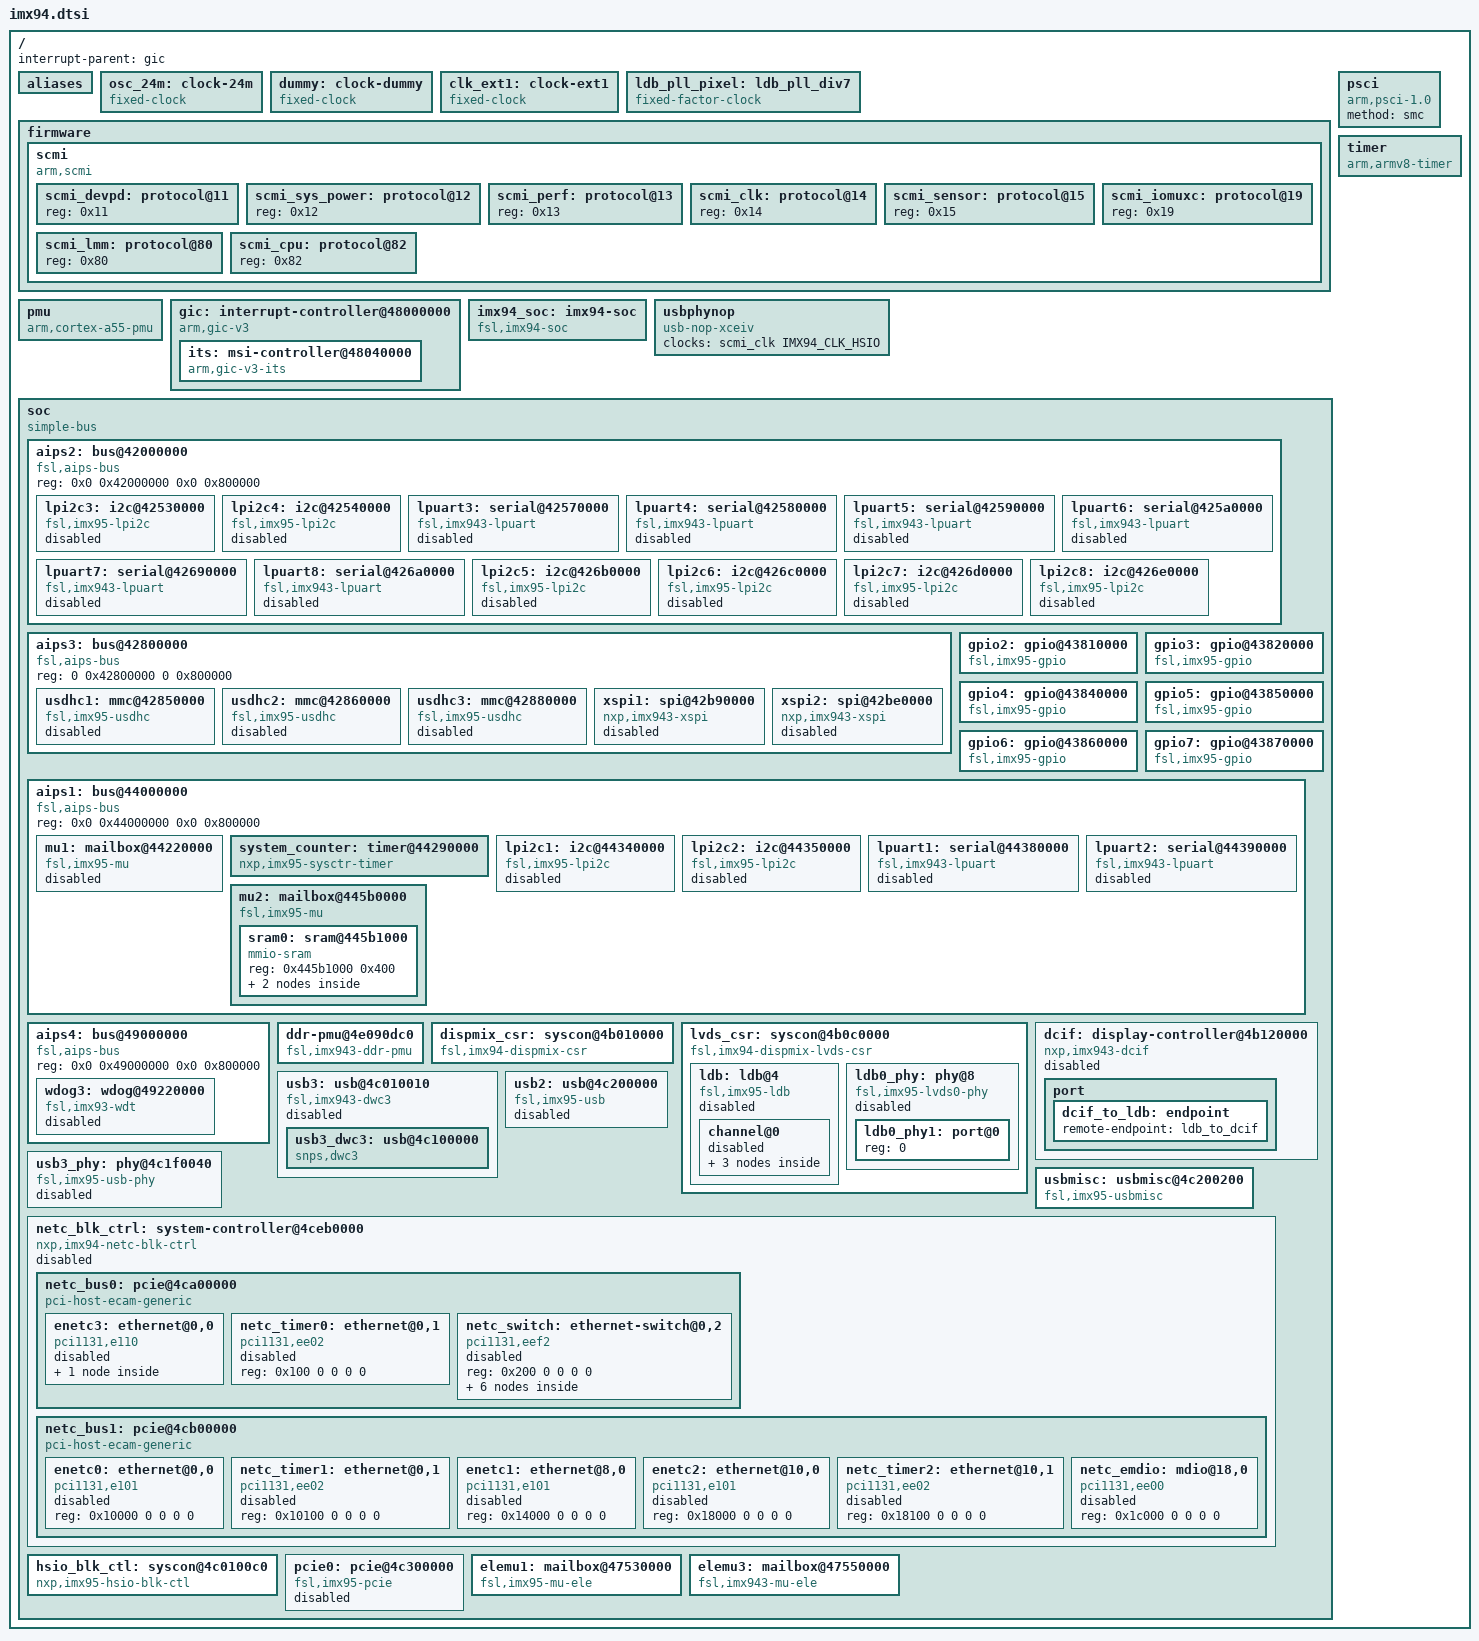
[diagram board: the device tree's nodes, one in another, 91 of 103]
// SPDX-License-Identifier: (GPL-2.0+ OR MIT)
/*
 * Copyright 2024-2025 NXP
 */

#include <dt-bindings/clock/nxp,imx94-clock.h>
#include <dt-bindings/gpio/gpio.h>
#include <dt-bindings/input/input.h>
#include <dt-bindings/interrupt-controller/arm-gic.h>
#include <dt-bindings/thermal/thermal.h>

#include "imx94-clock.h"
#include "imx94-pinfunc.h"
#include "imx94-power.h"

/ {
	#address-cells = <2>;
	#size-cells = <2>;
	interrupt-parent = <&gic>;

	aliases {
		gpio1 = &gpio2;
		gpio2 = &gpio3;
		gpio3 = &gpio4;
		gpio4 = &gpio5;
		gpio5 = &gpio6;
		gpio6 = &gpio7;
		i2c0 = &lpi2c1;
		i2c1 = &lpi2c2;
		i2c2 = &lpi2c3;
		i2c3 = &lpi2c4;
		i2c4 = &lpi2c5;
		i2c5 = &lpi2c6;
		i2c6 = &lpi2c7;
		i2c7 = &lpi2c8;
		mmc0 = &usdhc1;
		mmc1 = &usdhc2;
		mmc2 = &usdhc3;
		serial0 = &lpuart1;
		serial1 = &lpuart2;
		serial2 = &lpuart3;
		serial3 = &lpuart4;
		serial4 = &lpuart5;
		serial5 = &lpuart6;
		serial6 = &lpuart7;
		serial7 = &lpuart8;
	};

	osc_24m: clock-24m {
		compatible = "fixed-clock";
		#clock-cells = <0>;
		clock-frequency = <24000000>;
		clock-output-names = "osc_24m";
	};

	dummy: clock-dummy {
		compatible = "fixed-clock";
		#clock-cells = <0>;
		clock-frequency = <0>;
		clock-output-names = "dummy";
	};

	clk_ext1: clock-ext1 {
		compatible = "fixed-clock";
		#clock-cells = <0>;
		clock-frequency = <133000000>;
		clock-output-names = "clk_ext1";
	};

	ldb_pll_pixel: ldb_pll_div7 {
		#clock-cells = <0>;
		compatible = "fixed-factor-clock";
		clocks = <&scmi_clk IMX94_CLK_LDBPLL>;
		clock-div = <7>;
		clock-mult = <1>;
		clock-output-names = "ldb_pll_div7";
	};

	firmware {
		scmi {
			compatible = "arm,scmi";
			#address-cells = <1>;
			#size-cells = <0>;
			mboxes = <&mu2 5 0>, <&mu2 3 0>, <&mu2 3 1>;
			shmem = <&scmi_buf0>;

			scmi_devpd: protocol@11 {
				reg = <0x11>;
				#power-domain-cells = <1>;
			};

			scmi_sys_power: protocol@12 {
				reg = <0x12>;
			};

			scmi_perf: protocol@13 {
				reg = <0x13>;
				#power-domain-cells = <1>;
			};

			scmi_clk: protocol@14 {
				reg = <0x14>;
				#clock-cells = <1>;
			};

			scmi_sensor: protocol@15 {
				reg = <0x15>;
				#thermal-sensor-cells = <1>;
			};

			scmi_iomuxc: protocol@19 {
				reg = <0x19>;
			};

			scmi_lmm: protocol@80 {
				reg = <0x80>;
			};

			scmi_cpu: protocol@82 {
				reg = <0x82>;
			};
		};
	};

	pmu {
		compatible = "arm,cortex-a55-pmu";
		interrupts = <GIC_PPI 7 (GIC_CPU_MASK_SIMPLE(6) | IRQ_TYPE_LEVEL_HIGH)>;
	};

	psci {
		compatible = "arm,psci-1.0";
		method = "smc";
	};

	timer {
		compatible = "arm,armv8-timer";
		interrupts = <GIC_PPI 13 (GIC_CPU_MASK_SIMPLE(6) | IRQ_TYPE_LEVEL_LOW)>,
			     <GIC_PPI 14 (GIC_CPU_MASK_SIMPLE(6) | IRQ_TYPE_LEVEL_LOW)>,
			     <GIC_PPI 11 (GIC_CPU_MASK_SIMPLE(6) | IRQ_TYPE_LEVEL_LOW)>,
			     <GIC_PPI 10 (GIC_CPU_MASK_SIMPLE(6) | IRQ_TYPE_LEVEL_LOW)>;
		clock-frequency = <24000000>;
		interrupt-parent = <&gic>;
		arm,no-tick-in-suspend;
	};

	gic: interrupt-controller@48000000 {
		compatible = "arm,gic-v3";
		reg = <0 0x48000000 0 0x10000>,
		      <0 0x48060000 0 0xc0000>;
		ranges;
		#interrupt-cells = <3>;
		interrupt-controller;
		interrupts = <GIC_PPI 9 IRQ_TYPE_LEVEL_HIGH>;
		#address-cells = <2>;
		#size-cells = <2>;
		dma-noncoherent;
		interrupt-parent = <&gic>;

		its: msi-controller@48040000 {
			compatible = "arm,gic-v3-its";
			reg = <0 0x48040000 0 0x20000>;
			#msi-cells = <1>;
			dma-noncoherent;
			msi-controller;
		};
	};

	imx94_soc: imx94-soc {
		compatible = "fsl,imx94-soc";
	};

	usbphynop: usbphynop {
		compatible = "usb-nop-xceiv";
		#phy-cells = <0>;
		clocks = <&scmi_clk IMX94_CLK_HSIO>;
		clock-names = "main_clk";
	};

	soc {
		compatible = "simple-bus";
		ranges;
		#address-cells = <2>;
		#size-cells = <2>;

		aips2: bus@42000000 {
			compatible = "fsl,aips-bus", "simple-bus";
			reg = <0x0 0x42000000 0x0 0x800000>;
			ranges = <0x42000000 0x0 0x42000000 0x8000000>;
			#address-cells = <1>;
			#size-cells = <1>;

			lpi2c3: i2c@42530000 {
				compatible = "fsl,imx95-lpi2c", "fsl,imx7ulp-lpi2c";
				reg = <0x42530000 0x10000>;
				interrupts = <GIC_SPI 67 IRQ_TYPE_LEVEL_HIGH>;
				#address-cells = <1>;
				#size-cells = <0>;
				clocks = <&scmi_clk IMX94_CLK_LPI2C3>,
					 <&scmi_clk IMX94_CLK_BUSWAKEUP>;
				clock-names = "per", "ipg";
				status = "disabled";
			};

			lpi2c4: i2c@42540000 {
				compatible = "fsl,imx95-lpi2c", "fsl,imx7ulp-lpi2c";
				reg = <0x42540000 0x10000>;
				interrupts = <GIC_SPI 68 IRQ_TYPE_LEVEL_HIGH>;
				#address-cells = <1>;
				#size-cells = <0>;
				clocks = <&scmi_clk IMX94_CLK_LPI2C4>,
					 <&scmi_clk IMX94_CLK_BUSWAKEUP>;
				clock-names = "per", "ipg";
				status = "disabled";
			};

			lpuart3: serial@42570000 {
				compatible = "fsl,imx943-lpuart", "fsl,imx8ulp-lpuart",
					     "fsl,imx7ulp-lpuart";
				reg = <0x42570000 0x1000>;
				interrupts = <GIC_SPI 74 IRQ_TYPE_LEVEL_HIGH>;
				clocks = <&scmi_clk IMX94_CLK_LPUART3>;
				clock-names = "ipg";
				dma-names = "rx", "tx";
				status = "disabled";
			};

			lpuart4: serial@42580000 {
				compatible = "fsl,imx943-lpuart", "fsl,imx8ulp-lpuart",
					     "fsl,imx7ulp-lpuart";
				reg = <0x42580000 0x1000>;
				interrupts = <GIC_SPI 75 IRQ_TYPE_LEVEL_HIGH>;
				clocks = <&scmi_clk IMX94_CLK_LPUART4>;
				clock-names = "ipg";
				dma-names = "rx", "tx";
				status = "disabled";
			};

			lpuart5: serial@42590000 {
				compatible = "fsl,imx943-lpuart", "fsl,imx8ulp-lpuart",
					     "fsl,imx7ulp-lpuart";
				reg = <0x42590000 0x1000>;
				interrupts = <GIC_SPI 76 IRQ_TYPE_LEVEL_HIGH>;
				clocks = <&scmi_clk IMX94_CLK_LPUART5>;
				clock-names = "ipg";
				dma-names = "rx", "tx";
				status = "disabled";
			};

			lpuart6: serial@425a0000 {
				compatible = "fsl,imx943-lpuart", "fsl,imx8ulp-lpuart",
					     "fsl,imx7ulp-lpuart";
				reg = <0x425a0000 0x1000>;
				interrupts = <GIC_SPI 77 IRQ_TYPE_LEVEL_HIGH>;
				clocks = <&scmi_clk IMX94_CLK_LPUART6>;
				clock-names = "ipg";
				dma-names = "rx", "tx";
				status = "disabled";
			};

			lpuart7: serial@42690000 {
				compatible = "fsl,imx943-lpuart", "fsl,imx8ulp-lpuart",
					     "fsl,imx7ulp-lpuart";
				reg = <0x42690000 0x1000>;
				interrupts = <GIC_SPI 78 IRQ_TYPE_LEVEL_HIGH>;
				clocks = <&scmi_clk IMX94_CLK_LPUART7>;
				clock-names = "ipg";
				dma-names = "rx", "tx";
				status = "disabled";
			};

			lpuart8: serial@426a0000 {
				compatible = "fsl,imx943-lpuart", "fsl,imx8ulp-lpuart",
					     "fsl,imx7ulp-lpuart";
				reg = <0x426a0000 0x1000>;
				interrupts = <GIC_SPI 79 IRQ_TYPE_LEVEL_HIGH>;
				clocks = <&scmi_clk IMX94_CLK_LPUART8>;
				clock-names = "ipg";
				dma-names = "rx", "tx";
				status = "disabled";
			};

			lpi2c5: i2c@426b0000 {
				compatible = "fsl,imx95-lpi2c", "fsl,imx7ulp-lpi2c";
				reg = <0x426b0000 0x10000>;
				interrupts = <GIC_SPI 108 IRQ_TYPE_LEVEL_HIGH>;
				#address-cells = <1>;
				#size-cells = <0>;
				clocks = <&scmi_clk IMX94_CLK_LPI2C5>,
					 <&scmi_clk IMX94_CLK_BUSAON>;
				clock-names = "per", "ipg";
				status = "disabled";
			};

			lpi2c6: i2c@426c0000 {
				compatible = "fsl,imx95-lpi2c", "fsl,imx7ulp-lpi2c";
				reg = <0x426c0000 0x10000>;
				interrupts = <GIC_SPI 109 IRQ_TYPE_LEVEL_HIGH>;
				#address-cells = <1>;
				#size-cells = <0>;
				clocks = <&scmi_clk IMX94_CLK_LPI2C6>,
					 <&scmi_clk IMX94_CLK_BUSWAKEUP>;
				clock-names = "per", "ipg";
				status = "disabled";
			};

			lpi2c7: i2c@426d0000 {
				compatible = "fsl,imx95-lpi2c", "fsl,imx7ulp-lpi2c";
				reg = <0x426d0000 0x10000>;
				interrupts = <GIC_SPI 110 IRQ_TYPE_LEVEL_HIGH>;
				#address-cells = <1>;
				#size-cells = <0>;
				clocks = <&scmi_clk IMX94_CLK_LPI2C7>,
					 <&scmi_clk IMX94_CLK_BUSWAKEUP>;
				clock-names = "per", "ipg";
				status = "disabled";
			};

			lpi2c8: i2c@426e0000 {
				compatible = "fsl,imx95-lpi2c", "fsl,imx7ulp-lpi2c";
				reg = <0x426e0000 0x10000>;
				interrupts = <GIC_SPI 111 IRQ_TYPE_LEVEL_HIGH>;
				#address-cells = <1>;
				#size-cells = <0>;
				clocks = <&scmi_clk IMX94_CLK_LPI2C8>,
					 <&scmi_clk IMX94_CLK_BUSWAKEUP>;
				clock-names = "per", "ipg";
				status = "disabled";
			};
		};

		aips3: bus@42800000 {
			compatible = "fsl,aips-bus", "simple-bus";
			reg = <0 0x42800000 0 0x800000>;
			ranges = <0x42800000 0x0 0x42800000 0x800000>,
				 <0x28000000 0x0 0x28000000 0x1000000>;
			#address-cells = <1>;
			#size-cells = <1>;

			usdhc1: mmc@42850000 {
				compatible = "fsl,imx95-usdhc", "fsl,imx8mm-usdhc";
				reg = <0x42850000 0x10000>;
				interrupts = <GIC_SPI 96 IRQ_TYPE_LEVEL_HIGH>;
				clocks = <&scmi_clk IMX94_CLK_BUSWAKEUP>,
					 <&scmi_clk IMX94_CLK_WAKEUPAXI>,
					 <&scmi_clk IMX94_CLK_USDHC1>;
				clock-names = "ipg", "ahb", "per";
				assigned-clocks = <&scmi_clk IMX94_CLK_USDHC1>;
				assigned-clock-parents = <&scmi_clk IMX94_CLK_SYSPLL1_PFD1>;
				assigned-clock-rates = <400000000>;
				bus-width = <8>;
				fsl,tuning-start-tap = <1>;
				fsl,tuning-step = <2>;
				status = "disabled";
			};

			usdhc2: mmc@42860000 {
				compatible = "fsl,imx95-usdhc", "fsl,imx8mm-usdhc";
				reg = <0x42860000 0x10000>;
				interrupts = <GIC_SPI 97 IRQ_TYPE_LEVEL_HIGH>;
				clocks = <&scmi_clk IMX94_CLK_BUSWAKEUP>,
					 <&scmi_clk IMX94_CLK_WAKEUPAXI>,
					 <&scmi_clk IMX94_CLK_USDHC2>;
				clock-names = "ipg", "ahb", "per";
				assigned-clocks = <&scmi_clk IMX94_CLK_USDHC2>;
				assigned-clock-parents = <&scmi_clk IMX94_CLK_SYSPLL1_PFD1>;
				assigned-clock-rates = <200000000>;
				bus-width = <4>;
				fsl,tuning-start-tap = <1>;
				fsl,tuning-step = <2>;
				status = "disabled";
			};

			usdhc3: mmc@42880000 {
				compatible = "fsl,imx95-usdhc", "fsl,imx8mm-usdhc";
				reg = <0x42880000 0x10000>;
				interrupts = <GIC_SPI 116 IRQ_TYPE_LEVEL_HIGH>;
				clocks = <&scmi_clk IMX94_CLK_BUSWAKEUP>,
					 <&scmi_clk IMX94_CLK_WAKEUPAXI>,
					 <&scmi_clk IMX94_CLK_USDHC3>;
				clock-names = "ipg", "ahb", "per";
				assigned-clocks = <&scmi_clk IMX94_CLK_USDHC3>;
				assigned-clock-parents = <&scmi_clk IMX94_CLK_SYSPLL1_PFD1>;
				assigned-clock-rates = <200000000>;
				bus-width = <4>;
				fsl,tuning-start-tap = <1>;
				fsl,tuning-step = <2>;
				status = "disabled";
			};

			xspi1: spi@42b90000 {
				#address-cells = <1>;
				#size-cells = <0>;
				compatible = "nxp,imx943-xspi";
				reg = <0x42b90000 0x50000>, <0x28000000 0x08000000>;
				reg-names = "xspi_base", "xspi_mmap";
				interrupts = <GIC_SPI 390 IRQ_TYPE_LEVEL_HIGH>,       // EENV0
					     <GIC_SPI 391 IRQ_TYPE_LEVEL_HIGH>,	      // EENV1
					     <GIC_SPI 392 IRQ_TYPE_LEVEL_HIGH>,       // EENV2
					     <GIC_SPI 393 IRQ_TYPE_LEVEL_HIGH>,       // EENV3
					     <GIC_SPI 394 IRQ_TYPE_LEVEL_HIGH>;       // EENV4
				clocks = <&scmi_clk IMX94_CLK_XSPI1>;
				clock-names = "xspi";
				status = "disabled";
			};

			xspi2: spi@42be0000 {
				#address-cells = <1>;
				#size-cells = <0>;
				compatible = "nxp,imx943-xspi";
				reg = <0x42be0000 0x50000>, <0x24000000 0x04000000>;
				reg-names = "xspi_base", "xspi_mmap";
				interrupts = <GIC_SPI 395 IRQ_TYPE_LEVEL_HIGH>,
					     <GIC_SPI 396 IRQ_TYPE_LEVEL_HIGH>,	      // EENV1
					     <GIC_SPI 397 IRQ_TYPE_LEVEL_HIGH>,       // EENV2
					     <GIC_SPI 398 IRQ_TYPE_LEVEL_HIGH>,       // EENV3
					     <GIC_SPI 399 IRQ_TYPE_LEVEL_HIGH>;       // EENV4
				clocks = <&scmi_clk IMX94_CLK_XSPI2>;
				clock-names = "xspi";
				status = "disabled";
			};
		};

		gpio2: gpio@43810000 {
			compatible = "fsl,imx95-gpio", "fsl,imx8ulp-gpio";
			reg = <0x0 0x43810000 0x0 0x1000>;
			#interrupt-cells = <2>;
			interrupt-controller;
			interrupts = <GIC_SPI 54 IRQ_TYPE_LEVEL_HIGH>,
				     <GIC_SPI 55 IRQ_TYPE_LEVEL_HIGH>;
			#gpio-cells = <2>;
			gpio-controller;
			gpio-ranges = <&scmi_iomuxc 0 4 32>;
		};

		gpio3: gpio@43820000 {
			compatible = "fsl,imx95-gpio", "fsl,imx8ulp-gpio";
			reg = <0x0 0x43820000 0x0 0x1000>;
			#interrupt-cells = <2>;
			interrupt-controller;
			interrupts = <GIC_SPI 56 IRQ_TYPE_LEVEL_HIGH>,
				     <GIC_SPI 57 IRQ_TYPE_LEVEL_HIGH>;
			#gpio-cells = <2>;
			gpio-controller;
			gpio-ranges = <&scmi_iomuxc 0 36 26>;
		};

		gpio4: gpio@43840000 {
			compatible = "fsl,imx95-gpio", "fsl,imx8ulp-gpio";
			reg = <0x0 0x43840000 0x0 0x1000>;
			#interrupt-cells = <2>;
			interrupt-controller;
			interrupts = <GIC_SPI 58 IRQ_TYPE_LEVEL_HIGH>,
				     <GIC_SPI 59 IRQ_TYPE_LEVEL_HIGH>;
			#gpio-cells = <2>;
			gpio-controller;
			gpio-ranges = <&scmi_iomuxc 0 62 4>, <&scmi_iomuxc 4 0 4>,
				      <&scmi_iomuxc 8 140 12>, <&scmi_iomuxc 20 164 12>;
		};

		gpio5: gpio@43850000 {
			compatible = "fsl,imx95-gpio", "fsl,imx8ulp-gpio";
			reg = <0x0 0x43850000 0x0 0x1000>;
			#interrupt-cells = <2>;
			interrupt-controller;
			interrupts = <GIC_SPI 60 IRQ_TYPE_LEVEL_HIGH>,
				     <GIC_SPI 61 IRQ_TYPE_LEVEL_HIGH>;
			#gpio-cells = <2>;
			gpio-controller;
			gpio-ranges = <&scmi_iomuxc 0 108 32>;
		};

		gpio6: gpio@43860000 {
			compatible = "fsl,imx95-gpio", "fsl,imx8ulp-gpio";
			reg = <0x0 0x43860000 0x0 0x1000>;
			#interrupt-cells = <2>;
			interrupt-controller;
			interrupts = <GIC_SPI 62 IRQ_TYPE_LEVEL_HIGH>,
				     <GIC_SPI 63 IRQ_TYPE_LEVEL_HIGH>;
			#gpio-cells = <2>;
			gpio-controller;
			gpio-ranges = <&scmi_iomuxc 0 66 32>;
		};

		gpio7: gpio@43870000 {
			compatible = "fsl,imx95-gpio", "fsl,imx8ulp-gpio";
			reg = <0x0 0x43870000 0x0 0x1000>;
			#interrupt-cells = <2>;
			interrupt-controller;
			interrupts = <GIC_SPI 64 IRQ_TYPE_LEVEL_HIGH>,
				     <GIC_SPI 65 IRQ_TYPE_LEVEL_HIGH>;
			#gpio-cells = <2>;
			gpio-controller;
			gpio-ranges = <&scmi_iomuxc 0 98 10>, <&scmi_iomuxc 16 152 12>;
		};

		aips1: bus@44000000 {
			compatible = "fsl,aips-bus", "simple-bus";
			reg = <0x0 0x44000000 0x0 0x800000>;
			ranges = <0x44000000 0x0 0x44000000 0x800000>;
			#address-cells = <1>;
			#size-cells = <1>;

			mu1: mailbox@44220000 {
				compatible = "fsl,imx95-mu";
				reg = <0x44220000 0x10000>;
				interrupts = <GIC_SPI 262 IRQ_TYPE_LEVEL_HIGH>;
				clocks = <&scmi_clk IMX94_CLK_BUSAON>;
				#mbox-cells = <2>;
				status = "disabled";
			};

			system_counter: timer@44290000 {
				compatible = "nxp,imx95-sysctr-timer", "nxp,sysctr-timer";
				reg = <0x44290000 0x30000>;
				interrupts = <GIC_SPI 85 IRQ_TYPE_LEVEL_HIGH>;
				clocks = <&osc_24m>;
				clock-names = "per";
				nxp,no-divider;
			};

			lpi2c1: i2c@44340000 {
				compatible = "fsl,imx95-lpi2c", "fsl,imx7ulp-lpi2c";
				reg = <0x44340000 0x10000>;
				interrupts = <GIC_SPI 15 IRQ_TYPE_LEVEL_HIGH>;
				#address-cells = <1>;
				#size-cells = <0>;
				clocks = <&scmi_clk IMX94_CLK_LPI2C1>,
					 <&scmi_clk IMX94_CLK_BUSAON>;
				clock-names = "per", "ipg";
				status = "disabled";
			};

			lpi2c2: i2c@44350000 {
				compatible = "fsl,imx95-lpi2c", "fsl,imx7ulp-lpi2c";
				reg = <0x44350000 0x10000>;
				interrupts = <GIC_SPI 16 IRQ_TYPE_LEVEL_HIGH>;
				#address-cells = <1>;
				#size-cells = <0>;
				clocks = <&scmi_clk IMX94_CLK_LPI2C2>,
					 <&scmi_clk IMX94_CLK_BUSAON>;
				clock-names = "per", "ipg";
				status = "disabled";
			};

			lpuart1: serial@44380000 {
				compatible = "fsl,imx943-lpuart", "fsl,imx8ulp-lpuart",
					     "fsl,imx7ulp-lpuart";
				reg = <0x44380000 0x1000>;
				interrupts = <GIC_SPI 21 IRQ_TYPE_LEVEL_HIGH>;
				clocks = <&scmi_clk IMX94_CLK_LPUART1>;
				clock-names = "ipg";
				status = "disabled";
			};

			lpuart2: serial@44390000 {
				compatible = "fsl,imx943-lpuart", "fsl,imx8ulp-lpuart",
					     "fsl,imx7ulp-lpuart";
				reg = <0x44390000 0x1000>;
				interrupts = <GIC_SPI 22 IRQ_TYPE_LEVEL_HIGH>;
				clocks = <&scmi_clk IMX94_CLK_LPUART2>;
				clock-names = "ipg";
				status = "disabled";
			};

			mu2: mailbox@445b0000 {
				compatible = "fsl,imx95-mu";
				reg = <0x445b0000 0x1000>;
				ranges;
				interrupts = <GIC_SPI 264 IRQ_TYPE_LEVEL_HIGH>;
				#address-cells = <1>;
				#size-cells = <1>;
				#mbox-cells = <2>;

				sram0: sram@445b1000 {
					compatible = "mmio-sram";
					reg = <0x445b1000 0x400>;
					ranges = <0x0 0x445b1000 0x400>;
					#address-cells = <1>;
					#size-cells = <1>;

					scmi_buf0: scmi-sram-section@0 {
						compatible = "arm,scmi-shmem";
						reg = <0x0 0x400>;
					};

					scmi_buf1: scmi-sram-section@80 {
						compatible = "arm,scmi-shmem";
						reg = <0x80 0x80>;
					};
				};
			};
		};

		aips4: bus@49000000 {
			compatible = "fsl,aips-bus", "simple-bus";
			reg = <0x0 0x49000000 0x0 0x800000>;
			ranges = <0x49000000 0x0 0x49000000 0x800000>;
			#address-cells = <1>;
			#size-cells = <1>;

			wdog3: wdog@49220000 {
				compatible = "fsl,imx93-wdt";
				reg = <0x49220000 0x10000>;
				interrupts = <GIC_SPI 90 IRQ_TYPE_LEVEL_HIGH>;
				clocks = <&scmi_clk IMX94_CLK_BUSWAKEUP>;
				timeout-sec = <40>;
				fsl,ext-reset-output;
				status = "disabled";
			};
		};

		ddr-pmu@4e090dc0 {
			compatible = "fsl,imx943-ddr-pmu", "fsl,imx93-ddr-pmu";
			reg = <0x0 0x4e090dc0 0x0 0x200>;
			interrupts = <GIC_SPI 91 IRQ_TYPE_LEVEL_HIGH>;
		};

		dispmix_csr: syscon@4b010000 {
			compatible = "fsl,imx94-dispmix-csr", "syscon";
			#address-cells = <1>;
			#size-cells = <1>;
			reg = <0x0 0x4b010000 0x0 0x10000>;
			#clock-cells = <1>;
			clocks = <&scmi_clk IMX94_CLK_DISPAPB>;
			power-domains = <&scmi_devpd IMX94_PD_DISPLAY>;
			assigned-clocks = <&scmi_clk IMX94_CLK_DISPAXI>,
					  <&scmi_clk IMX94_CLK_DISPAPB>;
			assigned-clock-parents = <&scmi_clk IMX94_CLK_SYSPLL1_PFD1>,
						 <&scmi_clk IMX94_CLK_SYSPLL1_PFD1_DIV2>;
			assigned-clock-rates = <400000000>,  <133333333>;
		};

		lvds_csr: syscon@4b0c0000 {
			compatible = "fsl,imx94-dispmix-lvds-csr", "syscon";
			#address-cells = <1>;
			#size-cells = <1>;
			reg = <0x0 0x4b0c0000 0x0 0x10000>;
			#clock-cells = <1>;
			clocks = <&scmi_clk IMX94_CLK_DISPAPB>;
			power-domains = <&scmi_devpd IMX94_PD_DISPLAY>;

			ldb: ldb@4 {
				compatible = "fsl,imx95-ldb";
				#address-cells = <1>;
				#size-cells = <0>;
				reg = <0x4 0x4>;
				clocks = <&lvds_csr IMX94_CLK_DISPMIX_LVDS_CLK_GATE>,
					 <&dummy>, <&dummy>, <&dummy>;
				clock-names = "ldb_di0", "ldb_di1", "ldb_ch0", "ldb_ch1";
				status = "disabled";

				channel@0 {
					#address-cells = <1>;
					#size-cells = <0>;
					reg = <0>;
					phys = <&ldb0_phy1>;
					phy-names = "lvds_phy";
					status = "disabled";

					port@0 {
						reg = <0>;

						ldb_to_dcif: endpoint {
							remote-endpoint = <&dcif_to_ldb>;
						};
					};

					port@1 {
						reg = <1>;
					};
				};
			};

			ldb0_phy: phy@8 {
				compatible = "fsl,imx95-lvds0-phy";
				#address-cells = <1>;
				#size-cells = <0>;
				reg = <0x8 0x4>;
				gpr = <&lvds_csr>;
				clocks = <&scmi_clk IMX94_CLK_DISPAPB>;
				clock-names = "apb";
				power-domains = <&scmi_devpd IMX94_PD_DISPLAY>;
				status = "disabled";

				ldb0_phy1: port@0 {
					reg = <0>;
					#phy-cells = <0>;
				};
			};
		};

		dcif: display-controller@4b120000 {
			compatible = "nxp,imx943-dcif";
			reg = <0x0 0x4b120000 0x0 0x300000>;
			interrupts = <GIC_SPI 377 IRQ_TYPE_LEVEL_HIGH>,
				     <GIC_SPI 378 IRQ_TYPE_LEVEL_HIGH>,
				     <GIC_SPI 379 IRQ_TYPE_LEVEL_HIGH>;
			interrupt-names = "common", "back_layer", "fore_layer";
			clocks = <&scmi_clk IMX94_CLK_DISPPIX>,
				 <&scmi_clk IMX94_CLK_DISPAPB>,
				 <&scmi_clk IMX94_CLK_DISPAXI>,
				 <&ldb_pll_pixel>,
				 <&scmi_clk IMX94_CLK_LDBPLL_VCO>;
			clock-names = "pix", "apb", "axi", "ldb", "ldb_vco";
			power-domains = <&scmi_devpd IMX94_PD_DISPLAY>;
			nxp,blk-ctrl = <&dispmix_csr>;
			status = "disabled";

			port {
				dcif_to_ldb: endpoint {
					remote-endpoint = <&ldb_to_dcif>;
				};
			};
		};

		usb3: usb@4c010010 {
			compatible = "fsl,imx943-dwc3", "fsl,imx8mp-dwc3";
			reg = <0x0 0x4c010010 0x0 0x04>,
			      <0x0 0x4c1f0000 0x0 0x20>;
			clocks = <&scmi_clk IMX94_CLK_HSIO>,
				 <&scmi_clk IMX94_CLK_32K>;
			clock-names = "hsio", "suspend";
			interrupts = <GIC_SPI 386 IRQ_TYPE_LEVEL_HIGH>;
			#address-cells = <2>;
			#size-cells = <2>;
			ranges;
			power-domains = <&scmi_devpd IMX94_PD_HSIO_TOP>;
			status = "disabled";

			usb3_dwc3: usb@4c100000 {
				compatible = "snps,dwc3";
				reg = <0x0 0x4c100000 0x0 0x10000>;
				clocks = <&scmi_clk IMX94_CLK_HSIO>,
					 <&scmi_clk IMX94_CLK_24M>,
					 <&scmi_clk IMX94_CLK_32K>;
				clock-names = "bus_early", "ref", "suspend";
				interrupts = <GIC_SPI 180 IRQ_TYPE_LEVEL_HIGH>;
				phys = <&usb3_phy>, <&usb3_phy>;
				phy-names = "usb2-phy", "usb3-phy";
				snps,gfladj-refclk-lpm-sel-quirk;
				snps,parkmode-disable-ss-quirk;
			};
		};

		usb3_phy: phy@4c1f0040 {
			compatible = "fsl,imx95-usb-phy", "fsl,imx8mp-usb-phy";
			reg = <0x0 0x4c1f0040 0x0 0x40>,
			      <0x0 0x4c1fc000 0x0 0x100>;
			clocks = <&scmi_clk IMX94_CLK_HSIO>;
			clock-names = "phy";
			#phy-cells = <0>;
			power-domains = <&scmi_devpd IMX94_PD_HSIO_TOP>;
			status = "disabled";
		};

		usb2: usb@4c200000 {
			compatible = "fsl,imx95-usb", "fsl,imx7d-usb", "fsl,imx27-usb";
			reg = <0x0 0x4c200000 0x0 0x200>;
			interrupts = <GIC_SPI 181 IRQ_TYPE_LEVEL_HIGH>,
				     <GIC_SPI 387 IRQ_TYPE_LEVEL_HIGH>;
			clocks = <&scmi_clk IMX94_CLK_HSIO>,
				 <&scmi_clk IMX94_CLK_32K>;
			clock-names = "usb_ctrl_root", "usb_wakeup_clk";
			power-domains = <&scmi_devpd IMX94_PD_HSIO_TOP>;
			phys = <&usbphynop>;
			fsl,usbmisc = <&usbmisc 0>;
			status = "disabled";
		};

		usbmisc: usbmisc@4c200200 {
			compatible = "fsl,imx95-usbmisc", "fsl,imx7d-usbmisc";
			#index-cells = <1>;
			reg = <0x0 0x4c200200 0x0 0x200>,
			      <0x0 0x4c010014 0x0 0x04>;
		};

		netc_blk_ctrl: system-controller@4ceb0000 {
			compatible = "nxp,imx94-netc-blk-ctrl";
			reg = <0x0 0x4ceb0000 0x0 0x10000>,
			      <0x0 0x4cec0000 0x0 0x10000>,
			      <0x0 0x4c810000 0x0 0x7C>;
			reg-names = "ierb", "prb", "netcmix";
			#address-cells = <2>;
			#size-cells = <2>;
			ranges;
			power-domains = <&scmi_devpd IMX94_PD_NETC>;
			status = "disabled";

			netc_bus0: pcie@4ca00000 {
				compatible = "pci-host-ecam-generic";
				reg = <0x0 0x4ca00000 0x0 0x100000>;
				#address-cells = <3>;
				#size-cells = <2>;
				device_type = "pci";
				linux,pci-domain = <0>;
				bus-range = <0x0 0x0>;
					 /* Switch BAR0 - non-prefetchable memory */
				ranges = <0x02000000 0x0 0x4cc00000  0x0 0x4cc00000  0x0 0x80000
					 /* ENETC 3 and Timer 0 BAR0 - non-prefetchable memory */
					 0x02000000 0x0 0x4cd40000  0x0 0x4cd40000  0x0 0x60000
					 /* Switch and Timer 0 BAR2 - prefetchable memory */
					 0x42000000 0x0 0x4ce00000  0x0 0x4ce00000  0x0 0x20000
					 /* ENETC 3 VF0-2 BAR0 - non-prefetchable memory */
					 0x02000000 0x0 0x4ce50000  0x0 0x4ce50000  0x0 0x30000
					 /* ENETC 3 VF0-2 BAR2 - prefetchable memory */
					 0x42000000 0x0 0x4ce80000  0x0 0x4ce80000  0x0 0x30000>;

				enetc3: ethernet@0,0 {
					compatible = "pci1131,e110";
					reg = <0x0 0 0 0 0>;
					phy-mode = "internal";
					status = "disabled";

					fixed-link {
						speed = <2500>;
						full-duplex;
						pause;
					};
				};

				netc_timer0: ethernet@0,1 {
					compatible = "pci1131,ee02";
					reg = <0x100 0 0 0 0>;
					status = "disabled";
				};

				netc_switch: ethernet-switch@0,2 {
					compatible = "pci1131,eef2", "nxp,imx943-netc-switch";
					reg = <0x200 0 0 0 0>;
					status = "disabled";

					netc_switch_ports: ports {
						#address-cells = <1>;
						#size-cells = <0>;

						/* External ports */
						netc_switch_port0: port@0 {
							reg = <0>;
							status = "disabled";
						};

						netc_switch_port1: port@1 {
							reg = <1>;
							status = "disabled";
						};

						netc_switch_port2: port@2 {
							reg = <2>;
							status = "disabled";
						};

						/* Internal port, a.k.a management port */
						netc_switch_port3: port@3 {
							reg = <3>;
							phy-mode = "internal";
							ethernet = <&enetc3>;
							status = "disabled";

							fixed-link {
								speed = <2500>;
								full-duplex;
								pause;
							};
						};
					};
				};
			};

			netc_bus1: pcie@4cb00000 {
				compatible = "pci-host-ecam-generic";
				reg = <0x0 0x4cb00000 0x0 0x100000>;
				#address-cells = <3>;
				#size-cells = <2>;
				device_type = "pci";
				linux,pci-domain = <1>;
				bus-range = <0x1 0x1>;
					 /* ENETC 0-2 BAR0 - non-prefetchable memory */
				ranges = <0x02000000 0x0 0x4cC80000  0x0 0x4cc80000  0x0 0xc0000
					 /* Timer 1-2 and EMDIO BAR0 - non-prefetchable memory */
					 0x02000000 0x0 0x4cda0000  0x0 0x4cda0000  0x0 0x60000
					 /* Timer 1-2 and EMDIO BAR2 - prefetchable memory */
					 0x42000000 0x0 0x4ce20000  0x0 0x4ce20000  0x0 0x30000>;

				enetc0: ethernet@0,0 {
					compatible = "pci1131,e101";
					reg = <0x10000 0 0 0 0>;
					status = "disabled";
				};

				netc_timer1: ethernet@0,1 {
					compatible = "pci1131,ee02";
					reg = <0x10100 0 0 0 0>;
					status = "disabled";
				};

				enetc1: ethernet@8,0 {
					compatible = "pci1131,e101";
					reg = <0x14000 0 0 0 0>;
					status = "disabled";
				};

				enetc2: ethernet@10,0 {
					compatible = "pci1131,e101";
					reg = <0x18000 0 0 0 0>;
					status = "disabled";
				};

				netc_timer2: ethernet@10,1 {
					compatible = "pci1131,ee02";
					reg = <0x18100 0 0 0 0>;
					status = "disabled";
				};

				netc_emdio: mdio@18,0 {
					compatible = "pci1131,ee00";
					reg = <0x1c000 0 0 0 0>;
					#address-cells = <1>;
					#size-cells = <0>;
					status = "disabled";
				};
			};
		};

		hsio_blk_ctl: syscon@4c0100c0 {
			compatible = "nxp,imx95-hsio-blk-ctl", "syscon";
			reg = <0x0 0x4c0100c0 0x0 0x1>;
			#clock-cells = <1>;
			power-domains = <&scmi_devpd IMX94_PD_HSIO_TOP>;
			clocks = <&dummy>;
		};

		pcie0: pcie@4c300000 {
			compatible = "fsl,imx95-pcie";
			reg = <0 0x4c300000 0 0x10000>,
			      <0 0x60100000 0 0xfe00000>,
			      <0 0x4c360000 0 0x10000>,
			      <0 0x4c340000 0 0x4000>;
			reg-names = "dbi", "config", "atu", "app";
			ranges = <0x81000000 0x0 0x00000000 0x0 0x6ff00000 0 0x00100000>,
				 <0x82000000 0x0 0x10000000 0x9 0x10000000 0 0x10000000>;
			#address-cells = <3>;
			#size-cells = <2>;
			device_type = "pci";
			linux,pci-domain = <2>;
			msi-map = <0x0 &its 0x10 0x1>,
				  <0x100 &its 0x11 0x7>;
			msi-map-mask = <0x1ff>; /* Suppose only 1 physic device connect */
			bus-range = <0x00 0xff>;
			num-lanes = <1>;
			num-viewport = <8>;
			interrupts = <GIC_SPI 364 IRQ_TYPE_LEVEL_HIGH>,
				     <GIC_SPI 364 IRQ_TYPE_LEVEL_HIGH>,
				     <GIC_SPI 364 IRQ_TYPE_LEVEL_HIGH>;
			interrupt-names = "msi", "pme", "intr";
			#interrupt-cells = <1>;
			interrupt-map-mask = <0 0 0 0x7>;
			interrupt-map = <0 0 0 1 &gic 0 0 GIC_SPI 360 IRQ_TYPE_LEVEL_HIGH>,
					<0 0 0 2 &gic 0 0 GIC_SPI 361 IRQ_TYPE_LEVEL_HIGH>,
					<0 0 0 3 &gic 0 0 GIC_SPI 362 IRQ_TYPE_LEVEL_HIGH>,
					<0 0 0 4 &gic 0 0 GIC_SPI 363 IRQ_TYPE_LEVEL_HIGH>;
			clocks = <&scmi_clk IMX94_CLK_HSIO>,
				 <&scmi_clk IMX94_CLK_HSIOPLL>,
				 <&scmi_clk IMX94_CLK_HSIOPLL_VCO>,
				 <&scmi_clk IMX94_CLK_HSIOPCIEAUX>,
				 <&hsio_blk_ctl 0>;
			clock-names = "pcie", "pcie_bus", "pcie_phy", "pcie_aux", "ref";
			assigned-clocks =<&scmi_clk IMX94_CLK_HSIOPLL_VCO>,
					 <&scmi_clk IMX94_CLK_HSIOPLL>,
					 <&scmi_clk IMX94_CLK_HSIOPCIEAUX>;
			assigned-clock-rates = <3600000000>, <100000000>, <10000000>;
			assigned-clock-parents = <0>, <0>,
						 <&scmi_clk IMX94_CLK_SYSPLL1_PFD1_DIV2>;
			power-domains = <&scmi_devpd IMX94_PD_HSIO_TOP>;
			fsl,max-link-speed = <3>;
			/* 0x10~0x17 stream id for pci0 */
			/*
			 * iommu-map = <0x000 &smmu 0x10 0x1>, <0x100 &smmu 0x11 0x7>;
			 * iommu-map-mask = <0x1ff>;
			 */
			status = "disabled";
		};

		elemu1: mailbox@47530000 {
			compatible = "fsl,imx95-mu-ele";
			reg = <0x0 0x47530000 0x0 0x10000>;
			interrupts = <GIC_SPI 24 IRQ_TYPE_LEVEL_HIGH>;
			#mbox-cells = <2>;
		};

		elemu3: mailbox@47550000 {
			compatible = "fsl,imx943-mu-ele";
			reg = <0x0 0x47550000 0x0 0x10000>;
			interrupts = <GIC_SPI 26 IRQ_TYPE_LEVEL_HIGH>;
			#mbox-cells = <2>;
		};
	};

};
